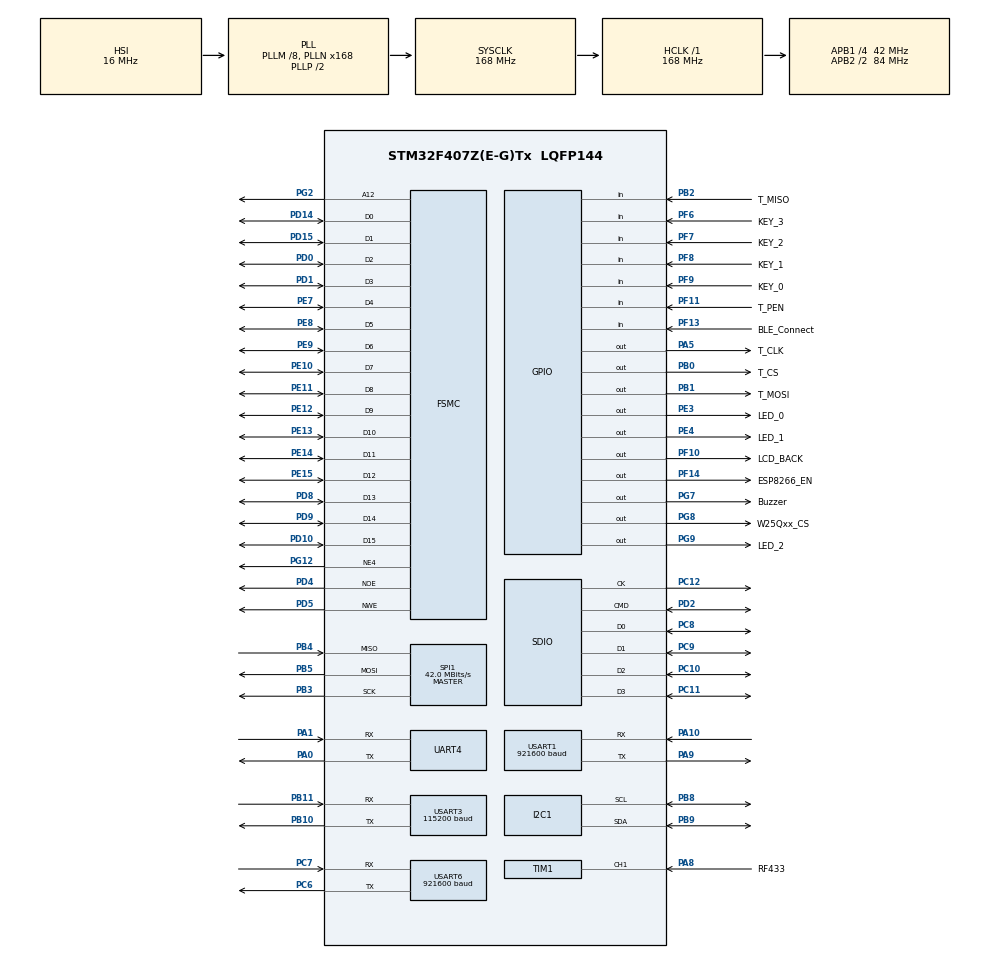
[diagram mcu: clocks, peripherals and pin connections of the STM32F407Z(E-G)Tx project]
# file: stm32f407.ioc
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Dma.Request0=USART3_RX
Dma.Request1=USART3_TX
Dma.Request2=UART4_RX
Dma.Request3=UART4_TX
Dma.Request4=SDIO_RX
Dma.Request5=SDIO_TX
Dma.Request6=USART1_RX
Dma.Request7=USART1_TX
Dma.Request8=USART6_RX
Dma.SDIO_RX.4.Direction=DMA_PERIPH_TO_MEMORY
Dma.SDIO_RX.4.FIFOMode=DMA_FIFOMODE_ENABLE
Dma.SDIO_RX.4.FIFOThreshold=DMA_FIFO_THRESHOLD_FULL
Dma.SDIO_RX.4.Instance=DMA2_Stream3
Dma.SDIO_RX.4.MemBurst=DMA_MBURST_INC4
Dma.SDIO_RX.4.MemDataAlignment=DMA_MDATAALIGN_WORD
Dma.SDIO_RX.4.MemInc=DMA_MINC_ENABLE
Dma.SDIO_RX.4.Mode=DMA_PFCTRL
Dma.SDIO_RX.4.PeriphBurst=DMA_PBURST_INC4
Dma.SDIO_RX.4.PeriphDataAlignment=DMA_PDATAALIGN_WORD
Dma.SDIO_RX.4.PeriphInc=DMA_PINC_DISABLE
Dma.SDIO_RX.4.Priority=DMA_PRIORITY_HIGH
Dma.SDIO_TX.5.Direction=DMA_MEMORY_TO_PERIPH
Dma.SDIO_TX.5.FIFOMode=DMA_FIFOMODE_ENABLE
Dma.SDIO_TX.5.FIFOThreshold=DMA_FIFO_THRESHOLD_FULL
Dma.SDIO_TX.5.Instance=DMA2_Stream6
Dma.SDIO_TX.5.MemBurst=DMA_MBURST_INC4
Dma.SDIO_TX.5.MemDataAlignment=DMA_MDATAALIGN_WORD
Dma.SDIO_TX.5.MemInc=DMA_MINC_ENABLE
Dma.SDIO_TX.5.Mode=DMA_PFCTRL
Dma.SDIO_TX.5.PeriphBurst=DMA_PBURST_INC4
Dma.SDIO_TX.5.PeriphDataAlignment=DMA_PDATAALIGN_WORD
Dma.SDIO_TX.5.PeriphInc=DMA_PINC_DISABLE
Dma.SDIO_TX.5.Priority=DMA_PRIORITY_HIGH
Dma.UART4_RX.2.Direction=DMA_PERIPH_TO_MEMORY
Dma.UART4_RX.2.FIFOMode=DMA_FIFOMODE_DISABLE
Dma.UART4_RX.2.Instance=DMA1_Stream2
Dma.UART4_RX.2.MemDataAlignment=DMA_MDATAALIGN_BYTE
Dma.UART4_RX.2.MemInc=DMA_MINC_ENABLE
Dma.UART4_RX.2.Mode=DMA_NORMAL
Dma.UART4_RX.2.PeriphDataAlignment=DMA_PDATAALIGN_BYTE
Dma.UART4_RX.2.PeriphInc=DMA_PINC_DISABLE
Dma.UART4_RX.2.Priority=DMA_PRIORITY_LOW
Dma.UART4_TX.3.Direction=DMA_MEMORY_TO_PERIPH
Dma.UART4_TX.3.FIFOMode=DMA_FIFOMODE_DISABLE
Dma.UART4_TX.3.Instance=DMA1_Stream4
Dma.UART4_TX.3.MemDataAlignment=DMA_MDATAALIGN_BYTE
Dma.UART4_TX.3.MemInc=DMA_MINC_ENABLE
Dma.UART4_TX.3.Mode=DMA_NORMAL
Dma.UART4_TX.3.PeriphDataAlignment=DMA_PDATAALIGN_BYTE
Dma.UART4_TX.3.PeriphInc=DMA_PINC_DISABLE
Dma.UART4_TX.3.Priority=DMA_PRIORITY_LOW
Dma.USART1_RX.6.Direction=DMA_PERIPH_TO_MEMORY
Dma.USART1_RX.6.FIFOMode=DMA_FIFOMODE_DISABLE
Dma.USART1_RX.6.Instance=DMA2_Stream2
Dma.USART1_RX.6.MemDataAlignment=DMA_MDATAALIGN_BYTE
Dma.USART1_RX.6.MemInc=DMA_MINC_ENABLE
Dma.USART1_RX.6.Mode=DMA_NORMAL
Dma.USART1_RX.6.PeriphDataAlignment=DMA_PDATAALIGN_BYTE
Dma.USART1_RX.6.PeriphInc=DMA_PINC_DISABLE
Dma.USART1_RX.6.Priority=DMA_PRIORITY_LOW
Dma.USART1_TX.7.Direction=DMA_MEMORY_TO_PERIPH
Dma.USART1_TX.7.FIFOMode=DMA_FIFOMODE_DISABLE
Dma.USART1_TX.7.Instance=DMA2_Stream7
Dma.USART1_TX.7.MemDataAlignment=DMA_MDATAALIGN_BYTE
Dma.USART1_TX.7.MemInc=DMA_MINC_ENABLE
Dma.USART1_TX.7.Mode=DMA_NORMAL
Dma.USART1_TX.7.PeriphDataAlignment=DMA_PDATAALIGN_BYTE
Dma.USART1_TX.7.PeriphInc=DMA_PINC_DISABLE
Dma.USART1_TX.7.Priority=DMA_PRIORITY_LOW
Dma.USART3_RX.0.Direction=DMA_PERIPH_TO_MEMORY
Dma.USART3_RX.0.FIFOMode=DMA_FIFOMODE_DISABLE
Dma.USART3_RX.0.Instance=DMA1_Stream1
Dma.USART3_RX.0.MemDataAlignment=DMA_MDATAALIGN_BYTE
Dma.USART3_RX.0.MemInc=DMA_MINC_ENABLE
Dma.USART3_RX.0.Mode=DMA_NORMAL
Dma.USART3_RX.0.PeriphDataAlignment=DMA_PDATAALIGN_BYTE
Dma.USART3_RX.0.PeriphInc=DMA_PINC_DISABLE
Dma.USART3_RX.0.Priority=DMA_PRIORITY_LOW
Dma.USART3_TX.1.Direction=DMA_MEMORY_TO_PERIPH
Dma.USART3_TX.1.FIFOMode=DMA_FIFOMODE_DISABLE
Dma.USART3_TX.1.Instance=DMA1_Stream3
Dma.USART3_TX.1.MemDataAlignment=DMA_MDATAALIGN_BYTE
Dma.USART3_TX.1.MemInc=DMA_MINC_ENABLE
Dma.USART3_TX.1.Mode=DMA_NORMAL
Dma.USART3_TX.1.PeriphDataAlignment=DMA_PDATAALIGN_BYTE
Dma.USART3_TX.1.PeriphInc=DMA_PINC_DISABLE
Dma.USART3_TX.1.Priority=DMA_PRIORITY_LOW
Dma.USART6_RX.8.Direction=DMA_PERIPH_TO_MEMORY
Dma.USART6_RX.8.FIFOMode=DMA_FIFOMODE_DISABLE
Dma.USART6_RX.8.Instance=DMA2_Stream1
Dma.USART6_RX.8.MemDataAlignment=DMA_MDATAALIGN_BYTE
Dma.USART6_RX.8.MemInc=DMA_MINC_ENABLE
Dma.USART6_RX.8.Mode=DMA_NORMAL
Dma.USART6_RX.8.PeriphDataAlignment=DMA_PDATAALIGN_BYTE
Dma.USART6_RX.8.PeriphInc=DMA_PINC_DISABLE
Dma.USART6_RX.8.Priority=DMA_PRIORITY_LOW
FATFS.USE_DMA_CODE_SD=1
FATFS._CODE_PAGE=936
FATFS._FS_EXFAT=0
FATFS._FS_TINY=0
FATFS._USE_LFN=3
I2C1.I2C_Mode=I2C_Fast
Mcu.Family=STM32F4
Mcu.Name=STM32F407Z(E-G)Tx
Mcu.Package=LQFP144
NVIC.DMA1_Stream1_IRQn=true\:6\:0\:true\:false\:true\:false\:true\:true
NVIC.DMA1_Stream2_IRQn=true\:6\:0\:true\:false\:true\:false\:true\:true
NVIC.DMA1_Stream3_IRQn=true\:6\:0\:true\:false\:true\:false\:true\:true
NVIC.DMA1_Stream4_IRQn=true\:6\:0\:true\:false\:true\:false\:true\:true
NVIC.DMA2_Stream1_IRQn=true\:0\:0\:false\:false\:true\:false\:true\:true
NVIC.DMA2_Stream2_IRQn=true\:0\:0\:false\:false\:true\:false\:true\:true
NVIC.DMA2_Stream3_IRQn=true\:6\:0\:true\:false\:true\:false\:true\:true
NVIC.DMA2_Stream6_IRQn=true\:6\:0\:true\:false\:true\:false\:true\:true
NVIC.DMA2_Stream7_IRQn=true\:0\:0\:false\:false\:true\:false\:true\:true
NVIC.I2C1_ER_IRQn=true\:0\:0\:false\:false\:true\:true\:true\:true
NVIC.I2C1_EV_IRQn=true\:0\:0\:false\:false\:true\:true\:true\:true
NVIC.PriorityGroup=NVIC_PRIORITYGROUP_4
NVIC.SDIO_IRQn=true\:0\:0\:true\:false\:true\:true\:true\:true
NVIC.SPI1_IRQn=true\:0\:0\:false\:false\:true\:true\:true\:true
NVIC.TIM1_CC_IRQn=true\:0\:0\:false\:false\:true\:true\:true\:true
NVIC.UART4_IRQn=true\:0\:0\:false\:false\:true\:true\:true\:true
NVIC.USART1_IRQn=true\:0\:0\:false\:false\:true\:true\:true\:true
NVIC.USART3_IRQn=true\:0\:0\:false\:false\:true\:true\:true\:true
NVIC.USART6_IRQn=true\:0\:0\:false\:false\:true\:true\:true\:true
PA0-WKUP.Mode=Asynchronous
PA0-WKUP.Signal=UART4_TX
PA1.Mode=Asynchronous
PA1.Signal=UART4_RX
PA10.Mode=Asynchronous
PA10.Signal=USART1_RX
PA13.Mode=Serial_Wire
PA13.Signal=SYS_JTMS-SWDIO
PA14.Mode=Serial_Wire
PA14.Signal=SYS_JTCK-SWCLK
PA5.GPIO_Label=T_CLK
PA5.GPIO_Speed=GPIO_SPEED_FREQ_VERY_HIGH
PA5.Signal=GPIO_Output
PA8.GPIO_Label=RF433
PA8.GPIO_PuPd=GPIO_NOPULL
PA8.GPIO_Speed=GPIO_SPEED_FREQ_VERY_HIGH
PA8.Signal=S_TIM1_CH1
PA9.Mode=Asynchronous
PA9.Signal=USART1_TX
PB0.GPIO_Label=T_CS
PB0.GPIO_Speed=GPIO_SPEED_FREQ_VERY_HIGH
PB0.PinState=GPIO_PIN_SET
PB0.Signal=GPIO_Output
PB1.GPIO_Label=T_MOSI
PB1.GPIO_Speed=GPIO_SPEED_FREQ_VERY_HIGH
PB1.Signal=GPIO_Output
PB10.Mode=Asynchronous
PB10.Signal=USART3_TX
PB11.Mode=Asynchronous
PB11.Signal=USART3_RX
PB2.GPIO_Label=T_MISO
PB2.GPIO_PuPd=GPIO_PULLUP
PB2.Signal=GPIO_Input
PB3.Mode=Full_Duplex_Master
PB3.Signal=SPI1_SCK
PB4.Mode=Full_Duplex_Master
PB4.Signal=SPI1_MISO
PB5.Mode=Full_Duplex_Master
PB5.Signal=SPI1_MOSI
PB8.Mode=I2C
PB8.Signal=I2C1_SCL
PB9.Mode=I2C
PB9.Signal=I2C1_SDA
PC10.Mode=SD_4_bits_Wide_bus
PC10.Signal=SDIO_D2
PC11.Mode=SD_4_bits_Wide_bus
PC11.Signal=SDIO_D3
PC12.Mode=SD_4_bits_Wide_bus
PC12.Signal=SDIO_CK
PC14-OSC32_IN.Mode=LSE-External-Oscillator
PC14-OSC32_IN.Signal=RCC_OSC32_IN
PC15-OSC32_OUT.Mode=LSE-External-Oscillator
PC15-OSC32_OUT.Signal=RCC_OSC32_OUT
PC6.Mode=Asynchronous
PC6.Signal=USART6_TX
PC7.Mode=Asynchronous
PC7.Signal=USART6_RX
PC8.Mode=SD_4_bits_Wide_bus
PC8.Signal=SDIO_D0
PC9.Mode=SD_4_bits_Wide_bus
PC9.Signal=SDIO_D1
PD0.Signal=FSMC_D2_DA2
PD1.Signal=FSMC_D3_DA3
PD10.Signal=FSMC_D15_DA15
PD14.Signal=FSMC_D0_DA0
PD15.Signal=FSMC_D1_DA1
PD2.Mode=SD_4_bits_Wide_bus
PD2.Signal=SDIO_CMD
PD4.Signal=FSMC_NOE
PD5.Signal=FSMC_NWE
PD8.Signal=FSMC_D13_DA13
PD9.Signal=FSMC_D14_DA14
PE10.Signal=FSMC_D7_DA7
PE11.Signal=FSMC_D8_DA8
PE12.Signal=FSMC_D9_DA9
PE13.Signal=FSMC_D10_DA10
PE14.Signal=FSMC_D11_DA11
PE15.Signal=FSMC_D12_DA12
PE3.GPIO_Label=LED_0
PE3.GPIO_Speed=GPIO_SPEED_FREQ_VERY_HIGH
PE3.PinState=GPIO_PIN_SET
PE3.Signal=GPIO_Output
PE4.GPIO_Label=LED_1
PE4.GPIO_Speed=GPIO_SPEED_FREQ_VERY_HIGH
PE4.PinState=GPIO_PIN_SET
PE4.Signal=GPIO_Output
PE7.Signal=FSMC_D4_DA4
PE8.Signal=FSMC_D5_DA5
PE9.Signal=FSMC_D6_DA6
PF10.GPIO_Label=LCD_BACK
PF10.GPIO_PuPd=GPIO_NOPULL
PF10.GPIO_Speed=GPIO_SPEED_FREQ_VERY_HIGH
PF10.Signal=GPIO_Output
PF11.GPIO_Label=T_PEN
PF11.GPIO_PuPd=GPIO_PULLUP
PF11.Signal=GPIO_Input
PF13.GPIO_Label=BLE_Connect
PF13.GPIO_PuPd=GPIO_NOPULL
PF13.Signal=GPIO_Input
PF14.GPIO_Label=ESP8266_EN
PF14.GPIO_Speed=GPIO_SPEED_FREQ_VERY_HIGH
PF14.Signal=GPIO_Output
PF6.GPIO_Label=KEY_3
PF6.GPIO_PuPd=GPIO_PULLUP
PF6.Signal=GPIO_Input
PF7.GPIO_Label=KEY_2
PF7.GPIO_PuPd=GPIO_PULLUP
PF7.Signal=GPIO_Input
PF8.GPIO_Label=KEY_1
PF8.GPIO_PuPd=GPIO_PULLUP
PF8.Signal=GPIO_Input
PF9.GPIO_Label=KEY_0
PF9.GPIO_PuPd=GPIO_PULLUP
PF9.Signal=GPIO_Input
PG12.Mode=NorPsramChipSelect4_1
PG12.Signal=FSMC_NE4
PG2.Signal=FSMC_A12
PG7.GPIO_Label=Buzzer
PG7.GPIO_Speed=GPIO_SPEED_FREQ_VERY_HIGH
PG7.Signal=GPIO_Output
PG8.GPIO_Label=W25Qxx_CS
PG8.GPIO_PuPd=GPIO_PULLUP
PG8.GPIO_Speed=GPIO_SPEED_FREQ_VERY_HIGH
PG8.PinState=GPIO_PIN_SET
PG8.Signal=GPIO_Output
PG9.GPIO_Label=LED_2
PG9.GPIO_Speed=GPIO_SPEED_FREQ_VERY_HIGH
PG9.PinState=GPIO_PIN_SET
PG9.Signal=GPIO_Output
PH0-OSC_IN.Mode=HSE-External-Oscillator
PH0-OSC_IN.Signal=RCC_OSC_IN
PH1-OSC_OUT.Mode=HSE-External-Oscillator
PH1-OSC_OUT.Signal=RCC_OSC_OUT
ProjectManager.HeapSize=0x1000
ProjectManager.StackSize=0x2000
ProjectManager.TargetToolchain=MDK-ARM V5.32
RCC.48MHZClocksFreq_Value=48000000
RCC.AHBFreq_Value=168000000
RCC.APB1CLKDivider=RCC_HCLK_DIV4
RCC.APB1Freq_Value=42000000
RCC.APB1TimFreq_Value=84000000
RCC.APB2CLKDivider=RCC_HCLK_DIV2
RCC.APB2Freq_Value=84000000
RCC.APB2TimFreq_Value=168000000
RCC.CortexFreq_Value=168000000
RCC.HCLKFreq_Value=168000000
RCC.HSE_VALUE=8000000
RCC.HSI_VALUE=16000000
RCC.PLLM=8
RCC.PLLN=168
RCC.PLLQ=7
RCC.RCC_RTC_Clock_Source=RCC_RTCCLKSOURCE_LSE
RCC.RCC_RTC_Clock_SourceVirtual=RCC_RTCCLKSOURCE_LSE
RCC.SYSCLKFreq_VALUE=168000000
RCC.SYSCLKSource=RCC_SYSCLKSOURCE_PLLCLK
RCC.VCOOutputFreq_Value=336000000
RTC.Date=14
RTC.Hours=20
RTC.Minutes=0
RTC.Month=RTC_MONTH_OCTOBER
RTC.WeekDay=RTC_WEEKDAY_TUESDAY
RTC.Year=25
SDIO.ClockDiv=4
SH.FSMC_A12.0=FSMC_A12,A12_1
SH.FSMC_D0_DA0.0=FSMC_D0,16b-d1
SH.FSMC_D10_DA10.0=FSMC_D10,16b-d1
SH.FSMC_D11_DA11.0=FSMC_D11,16b-d1
SH.FSMC_D12_DA12.0=FSMC_D12,16b-d1
SH.FSMC_D13_DA13.0=FSMC_D13,16b-d1
SH.FSMC_D14_DA14.0=FSMC_D14,16b-d1
SH.FSMC_D15_DA15.0=FSMC_D15,16b-d1
SH.FSMC_D1_DA1.0=FSMC_D1,16b-d1
SH.FSMC_D2_DA2.0=FSMC_D2,16b-d1
SH.FSMC_D3_DA3.0=FSMC_D3,16b-d1
SH.FSMC_D4_DA4.0=FSMC_D4,16b-d1
SH.FSMC_D5_DA5.0=FSMC_D5,16b-d1
SH.FSMC_D6_DA6.0=FSMC_D6,16b-d1
SH.FSMC_D7_DA7.0=FSMC_D7,16b-d1
SH.FSMC_D8_DA8.0=FSMC_D8,16b-d1
SH.FSMC_D9_DA9.0=FSMC_D9,16b-d1
SH.FSMC_NOE.0=FSMC_NOE,Lcd1
SH.FSMC_NWE.0=FSMC_NWE,Lcd1
SH.S_TIM1_CH1.0=TIM1_CH1,Input_Capture1_from_TI1
SPI1.BaudRatePrescaler=SPI_BAUDRATEPRESCALER_2
SPI1.CLKPhase=SPI_PHASE_2EDGE
SPI1.CLKPolarity=SPI_POLARITY_HIGH
SPI1.CRCCalculation=SPI_CRCCALCULATION_DISABLE
SPI1.CalculateBaudRate=42.0 MBits/s
SPI1.Direction=SPI_DIRECTION_2LINES
SPI1.Mode=SPI_MODE_MASTER
SPI1.VirtualType=VM_MASTER
TIM1.AutoReloadPreload=TIM_AUTORELOAD_PRELOAD_ENABLE
TIM1.Channel-Input_Capture1_from_TI1=TIM_CHANNEL_1
TIM1.Channel-Input_Capture2_from_TI1_63=TIM_CHANNEL_2
TIM1.ICFilter_CH1=8
TIM1.ICPolarity_CH2=TIM_INPUTCHANNELPOLARITY_FALLING
TIM1.Prescaler=16799
UART4.VirtualMode=Asynchronous
USART1.BaudRate=921600
USART1.VirtualMode=VM_ASYNC
USART3.BaudRate=115200
USART3.VirtualMode=VM_ASYNC
USART6.BaudRate=921600
USART6.VirtualMode=VM_ASYNC
VP_FATFS_VS_SDIO.Mode=SDIO
VP_RTC_VS_RTC_Activate.Mode=RTC_Enabled
VP_RTC_VS_RTC_Calendar.Mode=RTC_Calendar
VP_TIM1_VS_ClockSourceINT.Mode=Internal
VP_TIM1_VS_indirect_ch1.Mode=Input_Capture2_from_TI1_63
board=custom

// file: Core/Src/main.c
/* USER CODE BEGIN Header */
/**
 ******************************************************************************
 * @file           : main.c
 * @brief          : Main program body
 ******************************************************************************
 * @attention
 *
 * Copyright (c) 2025 STMicroelectronics.
 * All rights reserved.
 *
 * This software is licensed under terms that can be found in the LICENSE file
 * in the root directory of this software component.
 * If no LICENSE file comes with this software, it is provided AS-IS.
 *
 ******************************************************************************
 */
/* USER CODE END Header */
#include "main.h"
#include "dma.h"
#include "fatfs.h"
#include "i2c.h"
#include "rtc.h"
#include "sdio.h"
#include "spi.h"
#include "tim.h"
#include "usart.h"
#include "gpio.h"
#include "fsmc.h"

/* USER CODE BEGIN Includes */
/* https://www.zhihu.com/people/wang-shi-wei-67-38/posts */
#define LOG_TAG "main"
#include "elog.h"
/* USER CODE END Includes */

void SystemClock_Config(void);

int main(void)
{

  /* MCU Configuration--------------------------------------------------------*/

  /* Reset of all peripherals, Initializes the Flash interface and the Systick. */
  HAL_Init();

  /* Configure the system clock */
  SystemClock_Config();

  /* Initialize all configured peripherals */
  MX_GPIO_Init();
  MX_DMA_Init();
  MX_SPI1_Init();
  MX_USART6_UART_Init();
  MX_SDIO_SD_Init();
  MX_FATFS_Init();
  MX_UART4_Init();
  MX_USART3_UART_Init();
  MX_I2C1_Init();
  MX_FSMC_Init();
  MX_RTC_Init();
  MX_USART1_UART_Init();
  MX_TIM1_Init();
  /* USER CODE BEGIN 2 */
  app_init();
  app_run();

  /* USER CODE END 2 */

  /* Infinite loop */
  while (1)
  {

  }
}

void SystemClock_Config(void)
{
  RCC_OscInitTypeDef RCC_OscInitStruct = {0};
  RCC_ClkInitTypeDef RCC_ClkInitStruct = {0};

  /** Configure the main internal regulator output voltage
  */
  __HAL_RCC_PWR_CLK_ENABLE();
  __HAL_PWR_VOLTAGESCALING_CONFIG(PWR_REGULATOR_VOLTAGE_SCALE1);

  /** Initializes the RCC Oscillators according to the specified parameters
  * in the RCC_OscInitTypeDef structure.
  */
  RCC_OscInitStruct.OscillatorType = RCC_OSCILLATORTYPE_HSI|RCC_OSCILLATORTYPE_LSE;
  RCC_OscInitStruct.LSEState = RCC_LSE_ON;
  RCC_OscInitStruct.HSIState = RCC_HSI_ON;
  RCC_OscInitStruct.HSICalibrationValue = RCC_HSICALIBRATION_DEFAULT;
  RCC_OscInitStruct.PLL.PLLState = RCC_PLL_ON;
  RCC_OscInitStruct.PLL.PLLSource = RCC_PLLSOURCE_HSI;
  RCC_OscInitStruct.PLL.PLLM = 8;
  RCC_OscInitStruct.PLL.PLLN = 168;
  RCC_OscInitStruct.PLL.PLLP = RCC_PLLP_DIV2;
  RCC_OscInitStruct.PLL.PLLQ = 7;
  if (HAL_RCC_OscConfig(&RCC_OscInitStruct) != HAL_OK)
  {
    Error_Handler();
  }

  /** Initializes the CPU, AHB and APB buses clocks
  */
  RCC_ClkInitStruct.ClockType = RCC_CLOCKTYPE_HCLK|RCC_CLOCKTYPE_SYSCLK
                              |RCC_CLOCKTYPE_PCLK1|RCC_CLOCKTYPE_PCLK2;
  RCC_ClkInitStruct.SYSCLKSource = RCC_SYSCLKSOURCE_PLLCLK;
  RCC_ClkInitStruct.AHBCLKDivider = RCC_SYSCLK_DIV1;
  RCC_ClkInitStruct.APB1CLKDivider = RCC_HCLK_DIV4;
  RCC_ClkInitStruct.APB2CLKDivider = RCC_HCLK_DIV2;

  if (HAL_RCC_ClockConfig(&RCC_ClkInitStruct, FLASH_LATENCY_5) != HAL_OK)
  {
    Error_Handler();
  }
}

void Error_Handler(void)
{
  __disable_irq();
  while (1)
  {
  }
}
